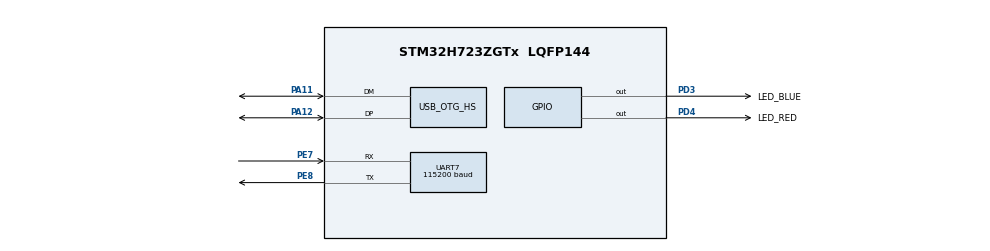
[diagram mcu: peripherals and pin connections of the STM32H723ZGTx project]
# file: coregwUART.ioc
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Dma.Request0=UART7_RX
Dma.UART7_RX.0.Direction=DMA_PERIPH_TO_MEMORY
Dma.UART7_RX.0.EventEnable=DISABLE
Dma.UART7_RX.0.FIFOMode=DMA_FIFOMODE_DISABLE
Dma.UART7_RX.0.Instance=DMA1_Stream5
Dma.UART7_RX.0.MemDataAlignment=DMA_MDATAALIGN_BYTE
Dma.UART7_RX.0.MemInc=DMA_MINC_ENABLE
Dma.UART7_RX.0.Mode=DMA_NORMAL
Dma.UART7_RX.0.PeriphDataAlignment=DMA_PDATAALIGN_BYTE
Dma.UART7_RX.0.PeriphInc=DMA_PINC_DISABLE
Dma.UART7_RX.0.Polarity=HAL_DMAMUX_REQ_GEN_RISING
Dma.UART7_RX.0.Priority=DMA_PRIORITY_LOW
Dma.UART7_RX.0.RequestNumber=1
Dma.UART7_RX.0.SignalID=NONE
Dma.UART7_RX.0.SyncEnable=DISABLE
Dma.UART7_RX.0.SyncPolarity=HAL_DMAMUX_SYNC_NO_EVENT
Dma.UART7_RX.0.SyncRequestNumber=1
Dma.UART7_RX.0.SyncSignalID=NONE
Mcu.Family=STM32H7
Mcu.Name=STM32H723ZGTx
Mcu.Package=LQFP144
NVIC.DMA1_Stream5_IRQn=true\:0\:0\:false\:false\:true\:false\:true\:true
NVIC.OTG_HS_IRQn=true\:0\:0\:false\:false\:true\:false\:true\:true
NVIC.PriorityGroup=NVIC_PRIORITYGROUP_4
NVIC.UART7_IRQn=true\:0\:0\:false\:false\:true\:true\:true\:true
PA11.Mode=Device_Only_FS
PA11.Signal=USB_OTG_HS_DM
PA12.Mode=Device_Only_FS
PA12.Signal=USB_OTG_HS_DP
PD3.GPIO_Label=LED_BLUE
PD3.Signal=GPIO_Output
PD4.GPIO_Label=LED_RED
PD4.Signal=GPIO_Output
PE7.Mode=Asynchronous
PE7.Signal=UART7_RX
PE8.Mode=Asynchronous
PE8.Signal=UART7_TX
PH0-OSC_IN.Mode=HSE-External-Oscillator
PH0-OSC_IN.Signal=RCC_OSC_IN
PH1-OSC_OUT.Mode=HSE-External-Oscillator
PH1-OSC_OUT.Signal=RCC_OSC_OUT
ProjectManager.HeapSize=0x200
ProjectManager.StackSize=0x400
ProjectManager.TargetToolchain=STM32CubeIDE
RCC.ADCFreq_Value=32250000
RCC.APB1Freq_Value=32000000
RCC.APB2Freq_Value=32000000
RCC.APB3Freq_Value=32000000
RCC.APB4Freq_Value=32000000
RCC.CortexFreq_Value=64000000
RCC.D1PPRE=RCC_APB3_DIV2
RCC.D2PPRE1=RCC_APB1_DIV2
RCC.D2PPRE2=RCC_APB2_DIV2
RCC.D3PPRE=RCC_APB4_DIV2
RCC.DIVM1=1
RCC.DIVN1=12
RCC.DIVQ1=4
RCC.HCLKFreq_Value=64000000
RCC.HSE_VALUE=16000000
RCC.PLL2FRACN=0
RCC.PLL3FRACN=0
RCC.PLLFRACN=0
RCC.PLLSourceVirtual=RCC_PLLSOURCE_HSE
RCC.SYSCLKFreq_VALUE=64000000
RCC.USBFreq_Value=48000000
UART7.BaudRate=115200
USB_DEVICE.CLASS_NAME_HS=CDC
USB_DEVICE.VirtualMode=Cdc
USB_DEVICE.VirtualModeHS=Cdc_HS
USB_OTG_HS.VirtualMode-Device_Only_FS=Device_Only_FS
VP_USB_DEVICE_VS_USB_DEVICE_CDC_HS.Mode=CDC_HS
board=custom

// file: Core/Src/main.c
/* USER CODE BEGIN Header */
/**
  ******************************************************************************
  * @file           : main.c
  * @brief          : Main program body
  ******************************************************************************
  * @attention
  *
  * Copyright (c) 2023 STMicroelectronics.
  * All rights reserved.
  *
  * This software is licensed under terms that can be found in the LICENSE file
  * in the root directory of this software component.
  * If no LICENSE file comes with this software, it is provided AS-IS.
  *
  ******************************************************************************
  */
/* USER CODE END Header */
#include "main.h"
#include "usb_device.h"
#include "usbd_cdc_if.h"

UART_HandleTypeDef huart7;
DMA_HandleTypeDef hdma_uart7_rx;

void SystemClock_Config(void);
static void MX_GPIO_Init(void);
static void MX_DMA_Init(void);
static void MX_UART7_Init(void);

/* USER CODE BEGIN 0 */
uint8_t UART_rxBuffer[IMU_UART_FRAME_SIZE] = {0}; // Create a buffer to store bytes received from UART

// This function is an interrupt called when the UART Transmit (TX) function has finished transmitting the buffer.
// This function toggles the BLUE LED for user readability
void HAL_UART_TxCpltCallback(UART_HandleTypeDef *huart)
{
//  HAL_UART_Transmit_IT(&huart7, data, sizeof (data));  // You may uncomment this for debug
	HAL_GPIO_TogglePin(LED_BLUE_GPIO_Port, LED_BLUE_Pin);
}

// This function is an interrupt called when the UART Received (RX) function has finished receiving IMU_UART_FRAME_SIZE bytes
// This function then sends the data over USB
void HAL_UART_RxCpltCallback(UART_HandleTypeDef *huart)
{
//  HAL_UART_Transmit(&huart7, UART_rxBuffer, IMU_UART_FRAME_SIZE, 100);  	// You may uncomment this line for debug
//	uint8_t buffer2[] = "Test";												// You may uncomment this line for debug
	CDC_Transmit_HS(UART_rxBuffer, sizeof(UART_rxBuffer));
    HAL_UART_Receive_DMA(&huart7, UART_rxBuffer, IMU_UART_FRAME_SIZE);
}

/* USER CODE END 0 */

int main(void)
{

  /* MCU Configuration--------------------------------------------------------*/

  /* Reset of all peripherals, Initializes the Flash interface and the Systick. */
  HAL_Init();

  /* Configure the system clock */
  SystemClock_Config();

  /* Initialize all configured peripherals */
  MX_GPIO_Init();
  MX_DMA_Init();
  MX_UART7_Init();
  MX_USB_DEVICE_Init();
  /* USER CODE BEGIN 2 */
  HAL_UART_Receive_DMA (&huart7, UART_rxBuffer, IMU_UART_FRAME_SIZE);  // Activate the listening and saving though DMA UART Receive (RX) function

  /*
  // Display a heder frame at startup // You may uncomment this for debug
  uint8_t buffer_header[] = "Demarrage de la passerelle!\r\n";
  CDC_Transmit_HS(buffer_header, sizeof(buffer_header));
  HAL_UART_Transmit_IT(&huart7, buffer_header, sizeof (buffer_header));
  */

  /* USER CODE END 2 */

  /* Infinite loop */
  /* USER CODE BEGIN WHILE */
  while (1)
  {
	  // Blink the RED LED to show the user that main loop is running.
	  HAL_GPIO_TogglePin(LED_RED_GPIO_Port, LED_RED_Pin);
	  HAL_Delay(1000);

/*	Send debug data on UART and USB  // You may uncomment this for debug
	  uint8_t buffer2[] = "Test\n";
	  CDC_Transmit_HS(buffer2, sizeof(buffer2));//
	  uint8_t data[] = "H W\n";
	  HAL_UART_Transmit_IT(&huart7, data, sizeof (data)); */

    /* USER CODE END WHILE */

  }
}

void SystemClock_Config(void)
{
  RCC_OscInitTypeDef RCC_OscInitStruct = {0};
  RCC_ClkInitTypeDef RCC_ClkInitStruct = {0};

  /** Supply configuration update enable
  */
  HAL_PWREx_ConfigSupply(PWR_LDO_SUPPLY);

  /** Configure the main internal regulator output voltage
  */
  __HAL_PWR_VOLTAGESCALING_CONFIG(PWR_REGULATOR_VOLTAGE_SCALE3);

  while(!__HAL_PWR_GET_FLAG(PWR_FLAG_VOSRDY)) {}

  /** Initializes the RCC Oscillators according to the specified parameters
  * in the RCC_OscInitTypeDef structure.
  */
  RCC_OscInitStruct.OscillatorType = RCC_OSCILLATORTYPE_HSI|RCC_OSCILLATORTYPE_HSE;
  RCC_OscInitStruct.HSEState = RCC_HSE_ON;
  RCC_OscInitStruct.HSIState = RCC_HSI_DIV1;
  RCC_OscInitStruct.HSICalibrationValue = 64;
  RCC_OscInitStruct.PLL.PLLState = RCC_PLL_ON;
  RCC_OscInitStruct.PLL.PLLSource = RCC_PLLSOURCE_HSE;
  RCC_OscInitStruct.PLL.PLLM = 1;
  RCC_OscInitStruct.PLL.PLLN = 12;
  RCC_OscInitStruct.PLL.PLLP = 2;
  RCC_OscInitStruct.PLL.PLLQ = 4;
  RCC_OscInitStruct.PLL.PLLR = 2;
  RCC_OscInitStruct.PLL.PLLRGE = RCC_PLL1VCIRANGE_3;
  RCC_OscInitStruct.PLL.PLLVCOSEL = RCC_PLL1VCOWIDE;
  RCC_OscInitStruct.PLL.PLLFRACN = 0;
  if (HAL_RCC_OscConfig(&RCC_OscInitStruct) != HAL_OK)
  {
    Error_Handler();
  }

  /** Initializes the CPU, AHB and APB buses clocks
  */
  RCC_ClkInitStruct.ClockType = RCC_CLOCKTYPE_HCLK|RCC_CLOCKTYPE_SYSCLK
                              |RCC_CLOCKTYPE_PCLK1|RCC_CLOCKTYPE_PCLK2
                              |RCC_CLOCKTYPE_D3PCLK1|RCC_CLOCKTYPE_D1PCLK1;
  RCC_ClkInitStruct.SYSCLKSource = RCC_SYSCLKSOURCE_HSI;
  RCC_ClkInitStruct.SYSCLKDivider = RCC_SYSCLK_DIV1;
  RCC_ClkInitStruct.AHBCLKDivider = RCC_HCLK_DIV1;
  RCC_ClkInitStruct.APB3CLKDivider = RCC_APB3_DIV2;
  RCC_ClkInitStruct.APB1CLKDivider = RCC_APB1_DIV2;
  RCC_ClkInitStruct.APB2CLKDivider = RCC_APB2_DIV2;
  RCC_ClkInitStruct.APB4CLKDivider = RCC_APB4_DIV2;

  if (HAL_RCC_ClockConfig(&RCC_ClkInitStruct, FLASH_LATENCY_1) != HAL_OK)
  {
    Error_Handler();
  }
}

static void MX_UART7_Init(void)
{

  huart7.Instance = UART7;
  huart7.Init.BaudRate = 115200;
  huart7.Init.WordLength = UART_WORDLENGTH_8B;
  huart7.Init.StopBits = UART_STOPBITS_1;
  huart7.Init.Parity = UART_PARITY_NONE;
  huart7.Init.Mode = UART_MODE_TX_RX;
  huart7.Init.HwFlowCtl = UART_HWCONTROL_NONE;
  huart7.Init.OverSampling = UART_OVERSAMPLING_16;
  huart7.Init.OneBitSampling = UART_ONE_BIT_SAMPLE_DISABLE;
  huart7.Init.ClockPrescaler = UART_PRESCALER_DIV1;
  huart7.AdvancedInit.AdvFeatureInit = UART_ADVFEATURE_NO_INIT;
  if (HAL_UART_Init(&huart7) != HAL_OK)
  {
    Error_Handler();
  }
  if (HAL_UARTEx_SetTxFifoThreshold(&huart7, UART_TXFIFO_THRESHOLD_1_8) != HAL_OK)
  {
    Error_Handler();
  }
  if (HAL_UARTEx_SetRxFifoThreshold(&huart7, UART_RXFIFO_THRESHOLD_1_8) != HAL_OK)
  {
    Error_Handler();
  }
  if (HAL_UARTEx_DisableFifoMode(&huart7) != HAL_OK)
  {
    Error_Handler();
  }

}

static void MX_DMA_Init(void)
{

  /* DMA controller clock enable */
  __HAL_RCC_DMA1_CLK_ENABLE();

  /* DMA interrupt init */
  /* DMA1_Stream5_IRQn interrupt configuration */
  HAL_NVIC_SetPriority(DMA1_Stream5_IRQn, 0, 0);
  HAL_NVIC_EnableIRQ(DMA1_Stream5_IRQn);

}

static void MX_GPIO_Init(void)
{
  GPIO_InitTypeDef GPIO_InitStruct = {0};

  /* GPIO Ports Clock Enable */
  __HAL_RCC_GPIOH_CLK_ENABLE();
  __HAL_RCC_GPIOE_CLK_ENABLE();
  __HAL_RCC_GPIOA_CLK_ENABLE();
  __HAL_RCC_GPIOD_CLK_ENABLE();

  /*Configure GPIO pin Output Level */
  HAL_GPIO_WritePin(GPIOD, LED_BLUE_Pin|LED_RED_Pin, GPIO_PIN_RESET);

  /*Configure GPIO pins : LED_BLUE_Pin LED_RED_Pin */
  GPIO_InitStruct.Pin = LED_BLUE_Pin|LED_RED_Pin;
  GPIO_InitStruct.Mode = GPIO_MODE_OUTPUT_PP;
  GPIO_InitStruct.Pull = GPIO_NOPULL;
  GPIO_InitStruct.Speed = GPIO_SPEED_FREQ_LOW;
  HAL_GPIO_Init(GPIOD, &GPIO_InitStruct);

}

void Error_Handler(void)
{
  __disable_irq();
  while (1)
  {
  }
}
